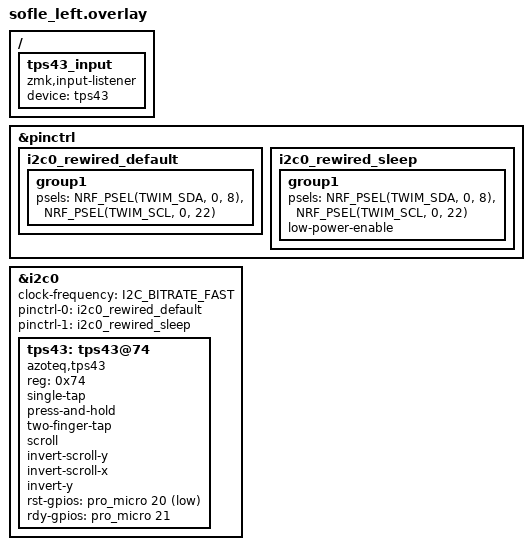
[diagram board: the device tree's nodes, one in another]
/*
 * Copyright (c) 2020 Ryan Cross
 *
 * SPDX-License-Identifier: MIT
 */

#include <zephyr/dt-bindings/i2c/i2c.h>
#include <dt-bindings/pinctrl/nrf-pinctrl.h>

&pinctrl {
    /* Rewire I2C0 to D0/D4 (P0.08/P0.22) for Azoteq TSP43 */
    i2c0_rewired_default: i2c0_rewired_default {
        group1 {
            psels = <NRF_PSEL(TWIM_SDA, 0, 8)>,
                    <NRF_PSEL(TWIM_SCL, 0, 22)>;
        };
    };

    i2c0_rewired_sleep: i2c0_rewired_sleep {
        group1 {
            psels = <NRF_PSEL(TWIM_SDA, 0, 8)>,
                    <NRF_PSEL(TWIM_SCL, 0, 22)>;
            low-power-enable;
        };
    };
};

&i2c0 {
    status = "okay";
    clock-frequency = <I2C_BITRATE_FAST>;

    pinctrl-0 = <&i2c0_rewired_default>;
    pinctrl-1 = <&i2c0_rewired_sleep>;
    pinctrl-names = "default", "sleep";

    tps43: tps43@74 {
        status = "okay";
        compatible = "azoteq,tps43";
        reg = <0x74>;

        single-tap;
        press-and-hold;
        two-finger-tap;

        scroll;
        invert-scroll-y;
        invert-scroll-x;

        invert-y;

        rst-gpios = <&pro_micro 20 GPIO_ACTIVE_LOW>;
        rdy-gpios = <&pro_micro 21 GPIO_ACTIVE_HIGH>;
    };
};

/ {
    tps43_input: tps43_input {
        compatible = "zmk,input-listener";
        device = <&tps43>;
    };
};
